AUTOSAR XML (schema 00049)
package /AUTOSAR/UpdateAndConfigurationManagement/AdaptiveApplicationSwComponentTypes_Blueprint
  adaptive application sw component type PKGMGR
    provide port PackageManagement
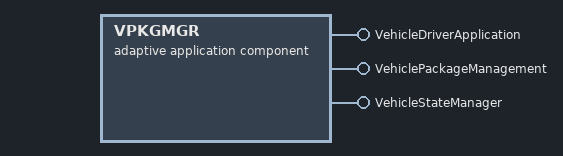
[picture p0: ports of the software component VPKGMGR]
  adaptive application sw component type VPKGMGR
    provide port VehicleDriverApplication
    provide port VehiclePackageManagement
    provide port VehicleStateManager
package /AUTOSAR/UpdateAndConfigurationManagement/ApApplicationErrors_Blueprint
  25 x ap application error, all with error-domain=UCMErrorDomain:
    NewCampaignDisabled: error-code=31  # New campaigns are disabled, calling AllowCampaign will enable new campaigns.
    UnexpectedPackage: error-code=32  # The Software Package name does not correspond to the RequestedPackage field value.
    IncorrectBlock: error-code=2  # The same block number is received twice.
    IncorrectBlockSize: error-code=30  # The size of the block exceeds the provided block size from TransferStart or TransferVehiclePackage.
    AuthenticationFailed: error-code=8  # Package authentication failed.
    BlockInconsistent: error-code=25  # Consistency check for transferred block failed.
    CancelFailed: error-code=16  # Cancel failed.
    IncompatibleDelta: error-code=29  # Delta package dependency check failed.
    IncompatiblePackageVersion: error-code=24  # The version of the Software or Vehicle Package to be processed is not compatible with the current version of UCM or UCM Master.
    IncorrectSize: error-code=3  # The size of the Software or Vehicle Package exceeds the provided size in TransferStart.
    InsufficientComputationPower: error-code=28  # Insufficient computation power to perform the requested operation.
    InsufficientData: error-code=6  # TransferExit has been called but total transferred data size does not match expected data size provided with TransferStart call.
    InsufficientMemory: error-code=1  # Insufficient memory to perform operation.
    InvalidPackageManifest: error-code=13  # Package manifest could not be read.
    InvalidTransferId: error-code=4  # The Transfer ID is invalid.
    MissingDependencies: error-code=21  # Activate cannot be performed because of missing dependencies.
    NotAbleToRevertPackages: error-code=15  # RevertProcessedSwPackages failed.
    NotAbleToRollback: error-code=18  # Rollback failed.
    OldVersion: error-code=9  # Software Package version is too old.
    OperationNotPermitted: error-code=5  # The operation is not supported in the current context.
    PackageInconsistent: error-code=7  # Package integrity check failed.
    ProcessSwPackageCancelled: error-code=22  # The processing operation has been interrupted by a Cancel() call.
    ProcessedSoftwarePackageInconsistent: error-code=23  # The processed Software Package integrity check has failed.
    ServiceBusy: error-code=12  # Another processing is already ongoing and therefore the current processing request has to be rejected.
    TransferInterrupted: error-code=26  # Transfer has been interrupted.
  ap application error domain UCMErrorDomain
  ap application error UpdateSessionRejected: error-code=33, error-domain=UCMErrorDomain  # Start of an update session was rejected by State Management
  ap application error PreActivationFailed: error-code=19, error-domain=UCMErrorDomain  # Error during preActivation step.
  ap application error VerificationFailed: error-code=27, error-domain=UCMErrorDomain  # Error during verification step.
package /AUTOSAR/UpdateAndConfigurationManagement/CompositionSwComponentTypes_Blueprint
  composition sw component type UCM
    component PKGMGR: type=PKGMGR
package /AUTOSAR/UpdateAndConfigurationManagement/ImplementationDataTypes_Blueprint
  30 x std cpp implementation data type:
    ActionType: compu {0x00=kUpdate (Update of a SoftwareCluster.), 0x01=kInstall (Installation of a new SoftwareCluster.), 0x02=kRemove (Removal of a SoftwareCluster.)}, range raw 0x00..0x02, type-reference=uint8_t  # Represents the UCM action.
      namespaces:
        symbol props ara
        symbol props ucm
        symbol props pkgmgr
    ByteVectorType: category=VECTOR, cpp-template-argument=uint8_t  # Byte vector representing raw data.
      namespaces:
        symbol props ara
        symbol props ucm
        symbol props pkgmgr
    CampaignStateType:  # Represents the status of Campaign.
      compu {0x00=kIdle (UCM Master is ready to start a software update campaign.), 0x01=kSyncing (UCM master is providing the list of installed SWCLs (GetSwClusterInfo) or computing the list of SWCLs to install (SwPackageInventory).), 0x02=kVehiclePackageTransferring (A vehicle package is being transferred to UCM Master.), 0x03=kSoftwarePackage_Transferring (UCM Master is transferring software packages to the UCM subordinates.), 0x04=kProcessing (The processing of software packages on UCM subordinates is ongoing. The transferring of software packages may still occur.), 0x05=kActivating (The activation of SWCLs on UCM subordinates is ongoing.), 0x06=kVehicleChecking (UCM Master is performing post-activation checks (OEM specific).), 0x07=kCancelling (UCM Master is rolling-back the activated SWCLs on the UCM subordinates.)}
      range raw 0x00..0x07
      type-reference=uint8_t
      namespaces:
        symbol props ara
        symbol props ucm
        symbol props pkgmgr
    TransferStateType: compu {0x00=kIdle (UCM Master is ready to start a software update campaign.), 0x01=kTransferring (Vehicle or Software Packages are being transferred.), 0x02=kUpdating (Software Clusters are being updated in the vehicle.), 0x03=kCancelling (An error occurred, campaign is being cancelled, reverting changes.)}, range raw 0x00..0x03, type-reference=uint8_t  # Represents the state of an update from OTA Client perspective.
      namespaces:
        symbol props ara
        symbol props ucm
        symbol props pkgmgr
    GetHistoryType: category=STRUCTURE  # Time refers to the activation time of the software cluster. It is represented in milliseconds of UCM’s action resolution since 01.01.1970 (UTC).
      namespaces:
        symbol props ara
        symbol props ucm
        symbol props pkgmgr
      5 x cpp implementation data type element:
        Time: type-reference={inplace=false, type-reference=uint64_t}  # Date and time of UCM’s action resolution.
        Name: type-reference={inplace=false, type-reference=SwNameType}  # Name of the SoftwareCluster
        Version: type-reference={inplace=false, type-reference=StrongRevisionLabelString}  # Version of the SoftwareCluster
        Action: type-reference={inplace=false, type-reference=ActionType}  # What action was performed by UCM
        Resolution: type-reference={inplace=false, type-reference=ResultType}  # What action was performed by UCM
    GetHistoryVectorType: category=VECTOR, cpp-template-argument=GetHistoryType  # Represents a list of UCM actions
      namespaces:
        symbol props ara
        symbol props ucm
        symbol props pkgmgr
    PackageManagerStatusType:  # Represents the state of UCM.
      compu {0x00=kIdle (UCM is ready to start processing if software packages are present.), 0x01=kReady (UCM has processed one or several packages and waits for additional packages, activation or reversion of processed packages.), 0x02=kProcessing (UCM is currently in the middle of processing a Software Package, i.e. a client has called ProcessSwPackage.), 0x03=kActivating (UCM is performing the dependency check and preparing the activation of the processed Software packages.), 0x04=kActivated (Software changes introduced with processed Software Packages has been activated and executed.), 0x05=kRollingBack (UCM is reverting changes introduced with processed packages.), 0x06=kRolledBack (Software changes introduced with processed Software Packages has been deactivated and original software is executed.), 0x07=kCleaningUp (Making sure that the system is in a clean state.), 0x08=kVerifying (UCM (via State Management) is checking that the processed packages have been properly restarted.)}
      range raw 0x00..0x08
      type-reference=uint8_t
      namespaces:
        symbol props ara
        symbol props ucm
        symbol props pkgmgr
    ResultType: compu {0x00=kSuccessfull (UCM’s action was successful.), 0x01=kFailed (UCM’s action failed.)}, range raw 0x00..0x01, type-reference=uint8_t  # Represents the result of UCM action.
      namespaces:
        symbol props ara
        symbol props ucm
        symbol props pkgmgr
    SafetyPolicyType: category=STRING  # The type of the Safety Policy.
      namespaces:
        symbol props ara
        symbol props ucm
        symbol props pkgmgr
    StrongRevisionLabelString: category=STRING  # Primitive type representing SoftwareCluster (SoftwarePackage) version.
      namespaces:
        symbol props ara
        symbol props ucm
        symbol props pkgmgr
    SwClusterInfoType: category=STRUCTURE  # Represents the information of a SoftwareCluster.
      namespaces:
        symbol props ara
        symbol props ucm
        symbol props pkgmgr
      cpp implementation data type element Name: type-reference={inplace=false, type-reference=SwNameType}  # Name of the SoftwareCluster
      cpp implementation data type element Version: type-reference={inplace=false, type-reference=StrongRevisionLabelString}  # SoftwareCluster version
      cpp implementation data type element State: type-reference={inplace=false, type-reference=SwClusterStateType}  # State of the SoftwareCluster
    SwClusterInfoVectorType: category=VECTOR, cpp-template-argument=SwClusterInfoType  # Represents a dynamic size array of SoftwareClusters
      namespaces:
        symbol props ara
        symbol props ucm
        symbol props pkgmgr
    SwClusterStateType: compu {0x00=kPresent (State of a SoftwareCluster that is installed on the adaptive platform and installation has finished.), 0x01=kAdded (State of a SoftwareCluster that has been newly installed.), 0x02=kUpdated (State of a SoftwareCluster that has been updated.), 0x03=kRemoved (State of a SoftwareCluster that has been removed.)}, range raw 0x00..0x03, type-reference=uint8_t  # Represents the state of a SoftwareCluster on the adaptive platform.
      namespaces:
        symbol props ara
        symbol props ucm
        symbol props pkgmgr
    SwDescType: category=STRUCTURE  # Contains general information related to SoftwareCluster that can be used by Vehicle Driver Application or Human Interface.
      namespaces:
        symbol props ara
        symbol props ucm
        symbol props pkgmgr
      6 x cpp implementation data type element:
        Name: type-reference={inplace=false, type-reference=SwNameType}  # SoftwareCluster name
        Version: type-reference={inplace=false, type-reference=StrongRevisionLabelString}  # SoftwareCluster version
        TypeApproval: type-reference={inplace=false, type-reference=string}  # TypeApproval carries the homologation information that may be specific for a given country.
        License: type-reference={inplace=false, type-reference=string}  # License has the full text of a license of the enclosing SoftwareCluster.
        ReleaseNotes: type-reference={inplace=false, type-reference=string}  # ReleaseNotes for the explanations of changes since the previous version.
        Size: type-reference={inplace=false, type-reference=uint64_t}  # Size of compressed Software Package or of Software Cluster.
    SwDescVectorType: category=VECTOR, cpp-template-argument=SwDescType  # Represents a dynamic size array of SoftwareCluster description
      namespaces:
        symbol props ara
        symbol props ucm
        symbol props pkgmgr
    SwNameType: category=STRING  # SoftwareCluster or SoftwarePackage shortName attribute inherited from referrable metaClass.
      namespaces:
        symbol props ara
        symbol props ucm
        symbol props pkgmgr
    SwNameVectorType: category=VECTOR, cpp-template-argument=SwNameType  # Represents a dynamic size array of Software Cluster names.
      namespaces:
        symbol props ara
        symbol props ucm
        symbol props pkgmgr
    SwNameVersionType: category=STRUCTURE  # Represents the information of a Software Package (Software Cluster) name and version.
      namespaces:
        symbol props ara
        symbol props ucm
        symbol props pkgmgr
      cpp implementation data type element Name: type-reference={inplace=false, type-reference=SwNameType}  # Software name
      cpp implementation data type element Version: type-reference={inplace=false, type-reference=StrongRevisionLabelString}  # Software version
    SwNameVersionVectorType: category=VECTOR, cpp-template-argument=SwNameVersionType  # Represents a dynamic size array of Software Name and Version
      namespaces:
        symbol props ara
        symbol props ucm
        symbol props pkgmgr
    SwPackageInfoType: category=STRUCTURE  # Represents the information of a Software Package.
      namespaces:
        symbol props ara
        symbol props ucm
        symbol props pkgmgr
      6 x cpp implementation data type element:
        Name: type-reference={inplace=false, type-reference=SwNameType}  # SoftwareCluster name
        Version: type-reference={inplace=false, type-reference=StrongRevisionLabelString}  # SoftwareCluster version
        TransferID: type-reference={inplace=false, type-reference=TransferIdType}  # TransferID of the Software Package
        ConsecutiveBytesReceived: type-reference={inplace=false, type-reference=uint64_t}  # Consecutive bytes received for the Software Package
        ConsecutiveBlocksReceived: type-reference={inplace=false, type-reference=uint64_t}  # Number of consecutive memory blocks received for the Software Package
        State: type-reference={inplace=false, type-reference=SwPackageStateType}  # State of the Software Package
    SwPackageInfoVectorType: category=VECTOR, cpp-template-argument=SwPackageInfoType  # Represents a dynamic size array of Software Packages
      namespaces:
        symbol props ara
        symbol props ucm
        symbol props pkgmgr
    SwPackageStateType:  # Represents the state of a Software Package on the Platform.
      compu {0x00=kTransferring (Software package is being transferred, i.e. not completely received.), 0x01=kTransferred (Software package is completely transferred and ready to be processed.), 0x02=kProcessing (Software package is currently being processed.), 0x03=kProcessed (Software package processing finished.), 0x04=kProcessingStream (Software package is being processed from a stream.)}
      range raw 0x00..0x04
      type-reference=uint8_t
      namespaces:
        symbol props ara
        symbol props ucm
        symbol props pkgmgr
    TransferIdType: category=ARRAY, array-size=16, cpp-template-argument{category=VALUE, inplace=true, template-type=uint8_t}  # Represents a handle identifier used to reference a particular transfer request.
      namespaces:
        symbol props ara
        symbol props ucm
        symbol props pkgmgr
    UCMIdentifierType: category=STRING  # UCM Module Instantiation Identifier.
      namespaces:
        symbol props ara
        symbol props ucm
        symbol props pkgmgr
    CampaignHistoryType: category=STRUCTURE  # Campaign history
      namespaces:
        symbol props ara
        symbol props ucm
        symbol props pkgmgr
      cpp implementation data type element CampaignError: type-reference={inplace=false, type-reference=CampaignErrorType}  # Campaign Error
      cpp implementation data type element HistoryVector: type-reference={inplace=false, type-reference=HistoryVectorType}  # History Vector
    HistoryVectorType: category=STRUCTURE  # History of an UCM
      namespaces:
        symbol props ara
        symbol props ucm
        symbol props pkgmgr
      cpp implementation data type element id: type-reference={inplace=false, type-reference=UCMIdentifierType}  # UCM's identifier
      cpp implementation data type element HistoryVector: type-reference={inplace=false, type-reference=GetHistoryVectorType}  # Returned vamue of UCM Subordinate from GetHistoryMethod
    UCMStepErrorType: category=STRUCTURE  # UCM Error
      namespaces:
        symbol props ara
        symbol props ucm
        symbol props pkgmgr
      cpp implementation data type element id: type-reference={inplace=false, type-reference=UCMIdentifierType}  # UCM's identifier
      cpp implementation data type element SoftwarePackageStep: type-reference={inplace=false, type-reference=SoftwarePackageStepType}  # Error occured at this Software Package Step as modelled in Vehicle Package
      cpp implementation data type element ReturnedError: type-reference={inplace=false, type-reference=uint8_t}  # Error returned from UCMErrorDomain
    CampaignErrorType: category=STRUCTURE  # Campaign Error
      namespaces:
        symbol props ara
        symbol props ucm
        symbol props pkgmgr
      cpp implementation data type element CampaignFailure: type-reference={inplace=false, type-reference=CampaignFailureType}  # Campaign failure
      cpp implementation data type element UCMStepError: type-reference={inplace=false, type-reference=UCMStepErrorType}  # Error from UCM at what Software Package Step
    SoftwarePackageStepType: compu {0x00=kTransfer (Software Package transfer), 0x01=kProcess (Software Package processing), 0x02=kPreActivate (Software Cluster pre activation), 0x03=kVerify (Software Cluster verification)}, range raw 0x00..0x03, type-reference=uint8_t  # UCM Software Package step at which error occured
      namespaces:
        symbol props ara
        symbol props ucm
        symbol props pkgmgr
    CampaignFailureType:  # Campaign failure
      compu {0x01=kUCMError (UCM error), 0x02=kInvalidVehiclePackageManifest (Vehicle Package manifest is invalid), 0x03=kSubordinateNotAvailableOnTheNetwork (UCM subordinate not reachable), 0x04=kVehicleStateManagerCommunicationError (Communication error with Vehicle State Manager), 0x05=kVehicleDriverInterfaceCommunicationError (Communication error with Vehicle Driver Interface), 0x06=kCampaignCancelled (Campaign was cancelled)}
      range raw 0x00..0x06
      type-reference=uint8_t
      namespaces:
        symbol props ara
        symbol props ucm
        symbol props pkgmgr
package /AUTOSAR/UpdateAndConfigurationManagement/LifeCycleInfoSets
  life cycle info set Requirements: default-lc-state=valid, used-life-cycle-state-definition-group=AutosarLifeCycleStates
    life-cycle-infos:
      lc-object=SWS_UCM_00173, lc-state=draft
      lc-object=SWS_UCM_00031, lc-state=draft
      lc-object=SWS_UCM_00071, lc-state=draft
      lc-object=SWS_UCM_{00174..00177}, lc-state=draft
      lc-object=SWS_UCM_00032, lc-state=draft
      lc-object=SWS_UCM_{00038..00040}, lc-state=draft
      lc-object=SWS_UCM_{00077..00079}, lc-state=draft
      lc-object=SWS_UCM_00044, lc-state=draft
      lc-object=SWS_UCM_{00132..00135}, lc-state=draft
      lc-object=SWS_UCM_01177, lc-state=draft
      lc-object=SWS_UCM_01114, lc-state=draft
      lc-object=SWS_UCM_00073, lc-state=draft
      lc-object=SWS_UCM_00131, lc-state=draft
      lc-object=SWS_UCM_00178, lc-state=draft
      lc-object=SWS_UCM_00181, lc-state=draft
      lc-object=SWS_UCM_00180, lc-state=draft
      lc-object=SWS_UCM_00182, lc-state=draft
      lc-object=SWS_UCM_00179, lc-state=draft
      lc-object=SWS_UCM_00183, lc-state=draft
      lc-object=SWS_UCM_00136, lc-state=draft
      lc-object=SWS_UCM_00186, lc-state=draft
      lc-object=SWS_UCM_00187, lc-state=draft
      lc-object=SWS_UCM_01178, lc-state=draft
      lc-object=SWS_UCM_{00251..00256}, lc-state=draft
package /AUTOSAR/UpdateAndConfigurationManagement/ServiceInterfaces_Blueprint
  4 x service interface, all with is-service=true:
    PackageManagement
      namespaces:
        symbol props ara
        symbol props ucm
        symbol props pkgmgr
      field CurrentStatus: type=PackageManagerStatusType, has-getter=true, has-notifier=true, has-setter=false  # The current status of UCM.
      methods:
        17 x operation, all with fire-and-forget=false:
          Activate: possible-ap-error=[MissingDependencies, OperationNotPermitted, UpdateSessionRejected, PreActivationFailed, VerificationFailed]  # This method activates the processed components.
          Cancel: possible-ap-error=[CancelFailed, InvalidTransferId, OperationNotPermitted]  # This method aborts an ongoing processing of a Software Package.
            arg id: type=TransferIdType, direction=IN  # The Transfer ID.
          DeleteTransfer: possible-ap-error=[InvalidTransferId, OperationNotPermitted]  # Delete a transferred Software Package.
            arg id: type=TransferIdType, direction=IN  # Transfer ID of the currently running request.
          Finish: possible-ap-error=OperationNotPermitted  # This method finishes the processing for the current set of processed Software Packages. It does a cleanup of all data of the processing including the sources of the Software Packages.
          GetHistory  # Getter method to retrieve all actions that have been performed by UCM.
            arg timestampGE: type=uint64_t, direction=IN  # Earliest timestamp (inclusive)
            arg timestampLT: type=uint64_t, direction=IN  # Latest timestamp (exclusive)
            arg history: type=GetHistoryVectorType, direction=OUT  # The history of all actions that have been performed by UCM.
          GetId  # Get the UCM Instance Identifier.
            arg id: type=UCMIdentifierType, direction=OUT  # UCM Module Instantiation Identifier.
          GetSwClusterChangeInfo  # This method returns a list pending changes to the set of SoftwareClusters on the adaptive platform. The returned list includes all SoftwareClusters that are to be added, updated or removed. The list of changes is extended in the course of processing Software Packages.
            arg SwInfo: type=SwClusterInfoVectorType, direction=OUT  # List of SoftwareClusters that are in state kAdded,kUpdated or kRemoved.
          GetSwClusterDescription  # This method returns the general information of the Software Clusters present in the platform
            arg SwCluster: type=SwDescVectorType, direction=OUT  # List of SoftwareClusters present in the platform.
          GetSwClusterInfo  # This method returns a list of SoftwareClusters that are in state kPresent.
            arg SwInfo: type=SwClusterInfoVectorType, direction=OUT  # List of installed SoftwareClusters that are in state kPresent.
          GetSwPackages  # This method returns the Software Packages that available in UCM.
            arg Packages: type=SwPackageInfoVectorType, direction=OUT  # List of Software Packages.
          GetSwProcessProgress: possible-ap-error=InvalidTransferId  # Get the progress (0 - 100%) of the currently processed Software Package.
            arg id: type=TransferIdType, direction=IN  # The Transfer ID of the Software Package.
            arg progress: type=uint8_t, direction=OUT, variation-point=blueprint-condition=note=p=l-1=Variation of Progress OUT parameter.  # The progress of the current package processing (0% - 100%). 0x00 ... 0x64, 0xFF for "‘No information available"’
          ProcessSwPackage: possible-ap-error=[AuthenticationFailed, IncompatibleDelta, IncompatiblePackageVersion, InsufficientComputationPower, InsufficientMemory, InvalidPackageManifest, InvalidTransferId, OperationNotPermitted, ProcessSwPackageCancelled, ProcessedSoftwarePackageInconsistent, ServiceBusy]  # Process a previously transferred Software Package.
            arg id: type=TransferIdType, direction=IN  # The Transfer ID of the Software Package which should be processed.
          RevertProcessedSwPackages: possible-ap-error=[NotAbleToRevertPackages, OperationNotPermitted]  # Revert the changes done by processing (ProcessSwPackage) of one or several software packages.
          Rollback: possible-ap-error=[NotAbleToRollback, OperationNotPermitted]  # Rollback the system to the state before the packages were processed.
          TransferData: possible-ap-error=[IncorrectBlock, IncorrectBlockSize, AuthenticationFailed, BlockInconsistent, IncompatiblePackageVersion, IncorrectSize, InsufficientComputationPower, InsufficientMemory, InvalidTransferId, OperationNotPermitted, PackageInconsistent, TransferInterrupted]  # Block-wise transfer of a Software Package to UCM.
            arg id: type=TransferIdType, direction=IN  # Transfer ID.
            arg data: type=ByteVectorType, direction=IN  # Data block of the Software Package.
            arg blockCounter: type=uint64_t, direction=IN  # Block counter value of the current block.
          TransferExit: possible-ap-error=[AuthenticationFailed, IncompatiblePackageVersion, InsufficientData, InvalidPackageManifest, InvalidTransferId, MissingDependencies, OldVersion, OperationNotPermitted, PackageInconsistent]  # Finish the transfer of a Software Package to UCM.
            arg id: type=TransferIdType, direction=IN  # Transfer ID of the currently running request.
          TransferStart: possible-ap-error=[InsufficientComputationPower, InsufficientMemory]  # Start the transfer of a Software Package. The size of the Software Package to be transferred to UCM must be provided. UCM will generate a Transfer ID for subsequent calls to TransferData, TransferExit, ProcessSwPackage, DeleteTransfer.
            arg size: type=uint64_t, direction=IN  # Size (in bytes) of the Software Package to be transferred.
            arg id: type=TransferIdType, direction=OUT  # Return TransferId.
            arg BlockSize: type=uint32_t, direction=OUT  # Size of the blocks to be received with TransferData method.
    VehicleDriverApplication
      4 x field, all with has-getter=true, has-notifier=true, has-setter=false:
        ApprovalRequired: type=bool  # Flag to inform Adaptive Application if approval from Vehicle Driver is required at current state based on Vehicle Package Manifest.
        CampaignState: type=CampaignStateType  # The current status of Campaign.
        SafetyPolicy: type=SafetyPolicyType  # Safety policy from the Vehicle Package to be computed by the Vehicle State Manager Adaptive Application.
        SafetyState: type=bool  # Vehicle state computed by the Vehicle State Manager Adaptive Application.
      methods:
        8 x operation, all with fire-and-forget=false:
          CancelCampaign: possible-ap-error=[CancelFailed, InvalidTransferId, OperationNotPermitted]  # This method aborts an ongoing campaign processing of a Vehicle Package.
            arg DisableCampaign: type=bool, direction=IN  # To forbid new campaign
          AllowCampaign  # To allow a new campaign to start
          DriverApproval  # Called by Adaptive Application to inform UCM Master of the driver's notification resolution (approve or reject)
            arg Approval: type=bool, direction=IN  # Driver's notification resolution
            arg SafetyPolicy: type=SafetyPolicyType, direction=IN  # Safety policy computed by the Vehicle State Manager Adaptive Application
          GetCampaignHistory  # Getter method to retrieve all actions that have been performed by UCM Master.
            arg timestampGE: type=uint64_t, direction=IN  # Earliest timestamp (inclusive)
            arg timestampLT: type=uint64_t, direction=IN  # Latest timestamp (exclusive)
            arg history: type=CampaignHistoryType, direction=OUT  # The history of all actions that have been performed by UCM Master.
          GetSwClusterDescription  # This method returns the general information of the Software Clusters present in the Adaptive Platform
            arg SoftwareClusterDescriptions: type=SwDescVectorType, direction=OUT  # List of SoftwareClusters general information
          GetSwPackageDescription  # This method returns the general information of the Software Packages that are part of current campaign handled by UCM Master.
            arg Packages: type=SwDescVectorType, direction=OUT  # List of Software Packages.
          GetSwProcessProgress  # Get the progress (0 - 100%) of the currently package processing.
            arg progress: type=uint8_t, direction=OUT, variation-point=blueprint-condition=note=p=l-1=Variation of Progress OUT parameter.  # The progress of the current package processing (0% - 100%). 0x00 ... 0x64, 0xFF for "‘No information available"’
          GetSwTransferProgress  # Get the progress (0 - 100%) of the currently package transferring.
            arg progress: type=uint8_t, direction=OUT, variation-point=blueprint-condition=note=p=l-1=Variation of Progress OUT parameter.  # The progress of the current package transferring (0% - 100%). 0x00 ... 0x64, 0xFF for "‘No information available"’
    VehiclePackageManagement
      namespaces:
        symbol props ara
        symbol props ucm
        symbol props pkgmgr
      field TransferState: type=TransferStateType, has-getter=true, has-notifier=true, has-setter=false  # The current status of Campaign from an OTA Client perspective.
      field RequestedPackage: type=SwNameVersionType, has-getter=true, has-notifier=true, has-setter=false  # Software Package to be transfered to UCM Master.
      field SafetyState: type=bool, has-getter=true, has-notifier=true, has-setter=false  # Vehicle state computed by the Vehicle State Manager Adaptive Application.
      methods:
        11 x operation, all with fire-and-forget=false:
          CancelCampaign: possible-ap-error=[CancelFailed, InvalidTransferId, OperationNotPermitted]  # This method aborts an ongoing campaign processing of a Vehicle Package.
            arg DisableCampaign: type=bool, direction=IN  # To forbid new campaign
          AllowCampaign  # To allow a new campaign to start
          DeleteTransfer: possible-ap-error=[InvalidTransferId, OperationNotPermitted]  # Delete a transferred Software or Vehicle Package.
            arg id: type=TransferIdType, direction=IN  # Transfer ID of the currently running request.
          GetCampaignHistory  # Getter method to retrieve all actions that have been performed by UCM Master.
            arg timestampGE: type=uint64_t, direction=IN  # Earliest timestamp (inclusive)
            arg timestampLT: type=uint64_t, direction=IN  # Latest timestamp (exclusive)
            arg CampaignHistory: type=CampaignHistoryType, direction=OUT  # The history of all actions that have been performed by UCM Master.
          GetSwClusterInfo  # This method returns a list of SoftwareClusters that are in state kPresent.
            arg SwInfo: type=SwClusterInfoVectorType, direction=OUT  # List of installed SoftwareClusters that are in state kPresent.
          GetSwPackages  # This method returns the Software Packages that are part of current campaign handled by UCM Master.
            arg Packages: type=SwPackageInfoVectorType, direction=OUT  # List of Software Packages.
          SwPackageInventory
            arg AvailableSoftwarePackages: type=SwNameVersionVectorType, direction=IN  # List of available Software Packages in Backend corresponding to VIN.
            arg RequiredSoftwarePackages: type=SwNameVersionVectorType, direction=OUT  # List of Software Packages to be sent to UCM Master.
          TransferData: possible-ap-error=[IncorrectBlock, IncorrectBlockSize, AuthenticationFailed, BlockInconsistent, IncompatiblePackageVersion, IncorrectSize, InsufficientComputationPower, InsufficientMemory, InvalidTransferId, OperationNotPermitted, PackageInconsistent, TransferInterrupted]  # Block-wise transfer of a Software or Vehicle Package to UCM Master.
            arg id: type=TransferIdType, direction=IN  # Transfer ID.
            arg data: type=ByteVectorType, direction=IN  # Data block of the Software or Vehicle Package.
            arg blockCounter: type=uint64_t, direction=IN  # Block counter value of the current block.
          TransferExit: possible-ap-error=[AuthenticationFailed, IncompatiblePackageVersion, InsufficientData, InvalidPackageManifest, InvalidTransferId, MissingDependencies, OldVersion, OperationNotPermitted, PackageInconsistent]  # Finish the transfer of a Software or Vehicle Package to UCM Master.
            arg id: type=TransferIdType, direction=IN  # Transfer ID of the currently running request.
          TransferStart: possible-ap-error=[UnexpectedPackage, InsufficientComputationPower, InsufficientMemory]  # Start the transfer of a Software Package. The name of the Software Package to be transferred to UCM Master must be provided. UCM Master will generate a Transfer ID for subsequent calls to TransferData, TransferExit, DeleteTransfer. Size of Software Package to be used to transfer to UCM subordinate is available in the Vehicle Package and its contained Software Package Manifests.
            arg SoftwarePackageName: type=SwNameType, direction=IN  # Software Package Short Name of the Software Package to be transferred.
            arg id: type=TransferIdType, direction=OUT  # Return TransferId.
            arg BlockSize: type=uint32_t, direction=OUT  # Size of the blocks to be received with TransferData method.
          TransferVehiclePackage: possible-ap-error=[NewCampaignDisabled, InsufficientMemory]  # Start the transfer of a Vehicle Package. The size of the Vehicle Package to be transferred to UCM Master must be provided. UCM Master will generate a Transfer ID for subsequent calls to TransferData, TransferExit, ProcessSwPackage, DeleteTransfer.
            arg size: type=uint64_t, direction=IN  # Size (in bytes) of the Vehicle Package to be transferred.
            arg id: type=TransferIdType, direction=OUT  # Return TransferId.
            arg BlockSize: type=uint32_t, direction=OUT  # Size of the blocks to be received with TransferData method.
    VehicleStateManager
      field SafetyPolicy: type=SafetyPolicyType, has-getter=true, has-notifier=true, has-setter=false  # Safety policy from the Vehicle Package to be computed by the Vehicle State Manager Adaptive Application.
      methods:
        operation SafetyState: fire-and-forget=false  # Method called by Vehicle State Manager Adaptive Application when safety state is changed
          arg SafetyPolicy: type=SafetyPolicyType, direction=IN  # Safety policy computed by the Vehicle State Manager Adaptive Application
          arg SafeToUpdate: type=bool, direction=OUT  # Vehicle safety state
